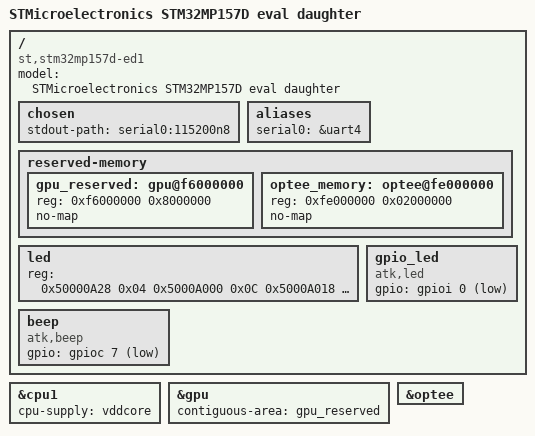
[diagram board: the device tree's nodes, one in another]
// SPDX-License-Identifier: (GPL-2.0+ OR BSD-3-Clause)
/*
 * Copyright (C) STMicroelectronics 2019 - All Rights Reserved
 * Author: Alexandre Torgue <alexandre.torgue@st.com> for STMicroelectronics.
 */
/dts-v1/;

#include "stm32mp157.dtsi"
#include "stm32mp15xd.dtsi"
#include "stm32mp15-pinctrl.dtsi"
#include "stm32mp15xxaa-pinctrl.dtsi"
#include "stm32mp157-m4-srm.dtsi"
#include "stm32mp157-m4-srm-pinctrl.dtsi"
#include "stm32mp157d-atk.dtsi"

/ {
	model = "STMicroelectronics STM32MP157D eval daughter";
	compatible = "st,stm32mp157d-ed1", "st,stm32mp157";

	chosen {
		stdout-path = "serial0:115200n8";
	};

	aliases {
		serial0 = &uart4;
	};

	reserved-memory {
		gpu_reserved: gpu@f6000000 {
			reg = <0xf6000000 0x8000000>;
			no-map;
		};

		optee_memory: optee@fe000000 {
			reg = <0xfe000000 0x02000000>;
			no-map;
		};
	};

	led{
		#address-cells = <1>;
		#size-cells = <1>;
		status = "okay";
		reg = <	0x50000A28 0x04 
				0x5000A000 0x0C
			   	0x5000A018 0x04 >;
	};

	gpio_led{
		compatible = "atk,led";
		status = "okay";
		gpio = <&gpioi 0 GPIO_ACTIVE_LOW>;
	};

	beep{
		compatible = "atk,beep";
		status = "okay";
		gpio = <&gpioc 7 GPIO_ACTIVE_LOW>;
	};
};

&cpu1{
	cpu-supply = <&vddcore>;
};

&gpu {
	contiguous-area = <&gpu_reserved>;
	status = "okay";
};

&optee {
	status = "okay";
};
